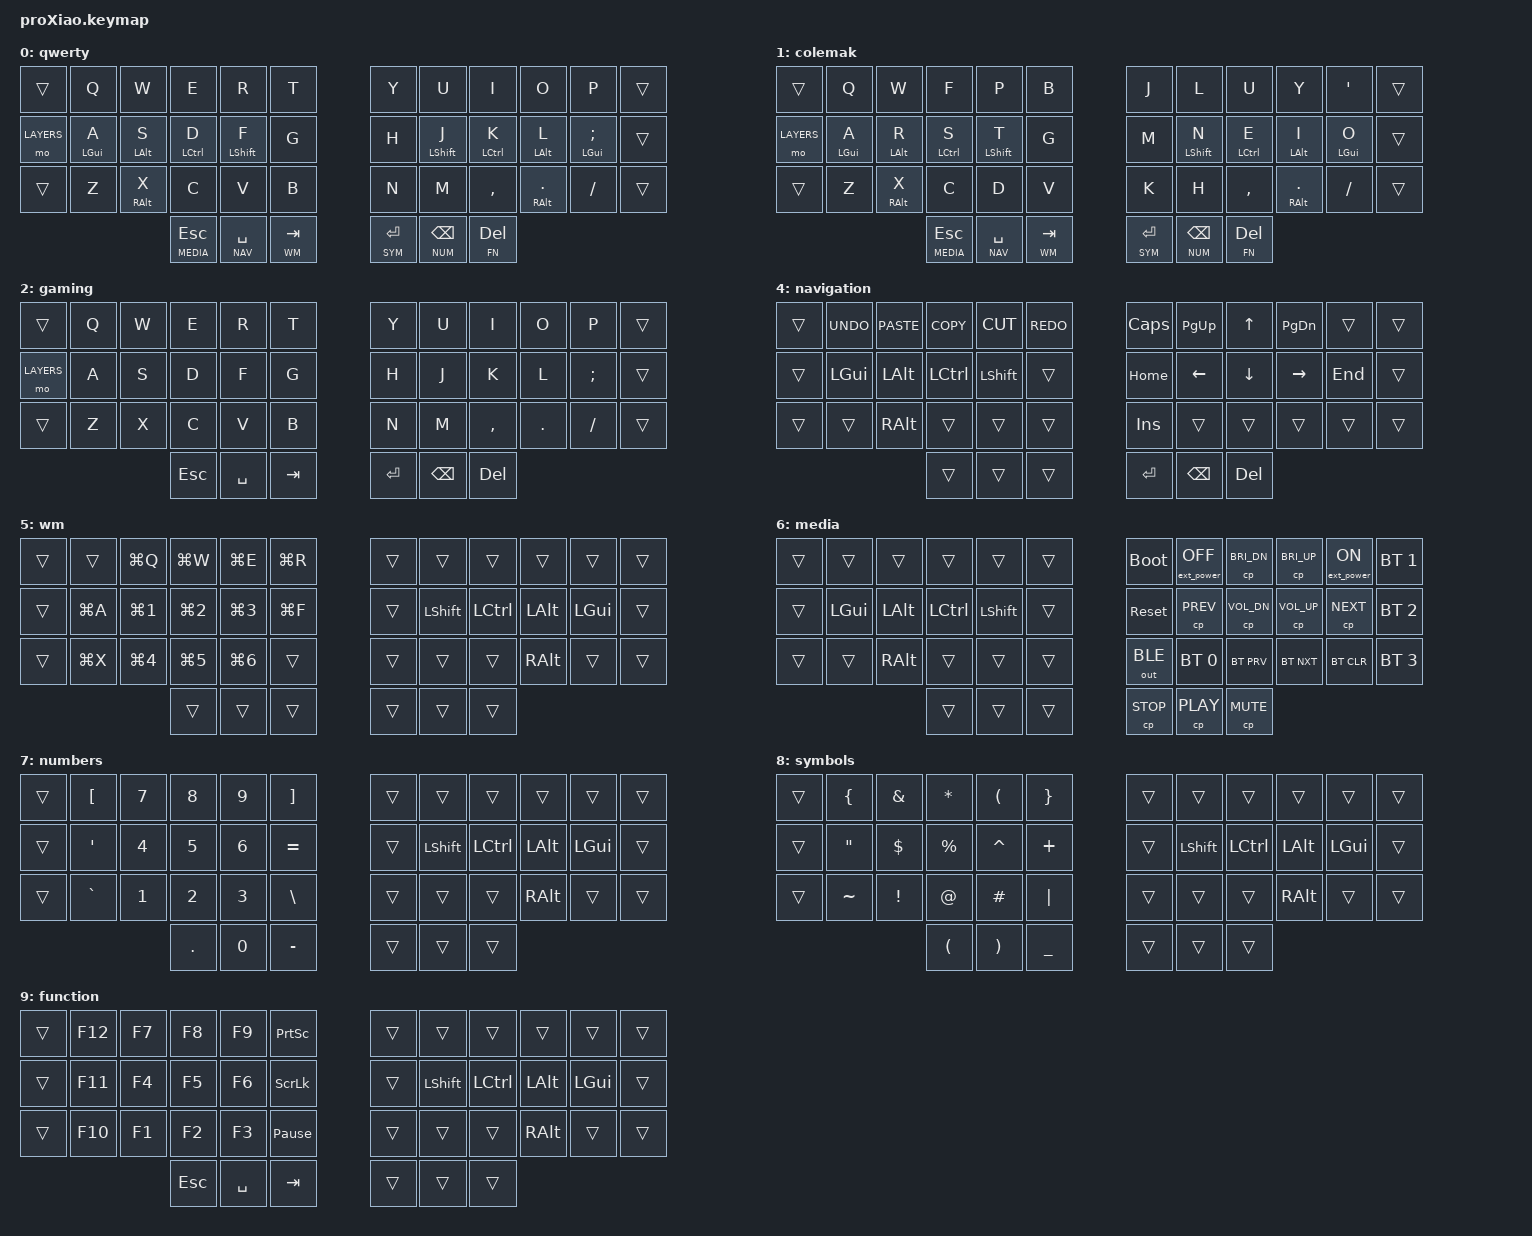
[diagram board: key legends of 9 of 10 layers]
// Jason Liu Layout for Corne 3
// https://github.com/jasoneliu/zmk-config/blob/main/config/corne.keymap
//

#include <behaviors.dtsi>
#include <dt-bindings/zmk/keys.h>
#include <dt-bindings/zmk/bt.h>
#include <dt-bindings/zmk/ext_power.h>
#include <dt-bindings/zmk/outputs.h>

#include "../zmk-nodefree-config/helper.h"
#include "includes/settings.dtsi"

// Layer Definitions
#define QWERTY 0
#define COLEMAK 1
#define GAMING 2
#define LAYERS 3
#define NAV 4
#define WM 5
#define MEDIA 6
#define NUM 7
#define SYM 8
#define FN 9

#define ___ &trans
#define QUICK_TAP_MS 175


/* Homerow mods */
#include "../zmk-nodefree-config/keypos_def/keypos_42keys.h"

#define KEYS_L LT0 LT1 LT2 LT3 LT4 LM0 LM1 LM2 LM3 LM4 LB0 LB1 LB2 LB3 LB4  // left hand
#define KEYS_R RT0 RT1 RT2 RT3 RT4 RM0 RM1 RM2 RM3 RM4 RB0 RB1 RB2 RB3 RB4  // right hand
#define THUMBS LH2 LH1 LH0 RH0 RH1 RH2                                      // thumbs

#define MAKE_HRM(NAME, HOLD, TAP, TRIGGER_POS) \
    ZMK_BEHAVIOR(NAME, hold_tap, \
        flavor = "balanced"; \
        tapping-term-ms = <280>; \
        quick-tap-ms = <QUICK_TAP_MS>; \
        require-prior-idle-ms = <150>; \
        bindings = <HOLD>, <TAP>; \
        hold-trigger-key-positions = <TRIGGER_POS>; \
        hold-trigger-on-release; \
    )
MAKE_HRM(hml, &kp, &kp, KEYS_R THUMBS)  // left-hand HRMs
MAKE_HRM(hmr, &kp, &kp, KEYS_L THUMBS)  // right-hand HRMs


// Keymap configuration (Colemak-DHm)
/ {
    keymap {
        compatible = "zmk,keymap";

        qwerty {
// -----------------------------------------------------------------------------------------------------------------------------
// |        |   Q    |   W    |     E     |     R     |     T     | # |     Y     |     U    |    I    |    O   |   P    |     |
// | LAYERS | A/LGUI | S/LALT |  D/LCTRL  |  F/LSHFT  |     G     | # |     H     | J/LSHFT  | K/LCTRR | L/LALT | ;/LGUI |     |
// |        |   Z    | X/RALT |     C     |     V     |     B     | # |     N     |     M    |    ,    | ./RALT |   /    |     |
//                            | ESC/MEDIA | SPACE/NAV | TAB/WM    | # | ENTER/SYM | BSPC/NUM | DEL/FN  |

            bindings = <
&trans      &kp Q       &kp W       &kp E          &kp R          &kp T                &kp Y          &kp U         &kp I          &kp O         &kp P          &trans
&mo LAYERS  &mt LGUI A  &mt LALT S  &mt LCTRL D    &mt LSHFT F    &kp G                &kp H          &mt LSHFT J   &mt LCTRL K    &mt LALT L    &mt LGUI SEMI  &trans
&trans      &kp Z       &mt RALT X  &kp C          &kp V          &kp B                &kp N          &kp M         &kp CMMA       &mt RALT DOT  &kp FSLH       &trans
                                    &lt MEDIA ESC  &lt NAV SPACE  &lt WM TAB           &lt SYM ENTER  &lt NUM BSPC  &lt FN DEL
            >;
        };

        colemak {
// -----------------------------------------------------------------------------------------------------------------------------
// |        |   Q    |   W    |     F     |     P     |     B     | # |     J     |    L     |    U    |    Y   |   '    |     |
// | LAYERS | A/LGUI | R/LALT |  S/LCTRL  |  T/LSHFT  |     G     | # |     M     | N/LSHFT  | E/LCTRL | I/LALT | O/LGUI |     |
// |        |   Z    | X/RALT |     C     |     D     |     V     | # |     K     |    H     |    ,    | ./RALT |   /    |     |
//                            | ESC/MEDIA | SPACE/NAV | TAB/WM    | # | ENTER/SYM | BSPC/NUM | DEL/FN  |

            bindings = <
&trans      &kp Q       &kp W       &kp F          &kp P          &kp B                &kp J          &kp L         &kp U          &kp Y         &kp SQT     &trans
&mo LAYERS  &mt LGUI A  &mt LALT R  &mt LCTRL S    &mt LSHFT T    &kp G                &kp M          &mt LSHFT N   &mt LCTRL E    &mt LALT I    &mt LGUI O  &trans
&trans      &kp Z       &mt RALT X  &kp C          &kp D          &kp V                &kp K          &kp H         &kp CMMA       &mt RALT DOT  &kp FSLH    &trans
                                    &lt MEDIA ESC  &lt NAV SPACE  &lt WM TAB           &lt SYM ENTER  &lt NUM BSPC  &lt FN DEL
            >;
        };

        gaming {
// ----------------------------------------------------------------------------------------------------
// |        |   Q   |   W   |   E   |   R   |   T   | # |   Y   |   U   |   I   |   O   |   P   |     |
// | LAYERS |   A   |   S   |   D   |   F   |   G   | # |   H   |   J   |   K   |   L   |   ;   |     |
// |        |   Z   |   X   |   C   |   V   |   B   | # |   N   |   M   |   ,   |   .   |   /   |     |
//                          |  ESC  | SPACE |  TAB  | # | ENTER | BSPC  |  DEL  |

            bindings = <
&trans      &kp Q  &kp W  &kp E    &kp R      &kp T          &kp Y      &kp U     &kp I     &kp O    &kp P     &trans
&mo LAYERS  &kp A  &kp S  &kp D    &kp F      &kp G          &kp H      &kp J     &kp K     &kp L    &kp SEMI  &trans
&trans      &kp Z  &kp X  &kp C    &kp V      &kp B          &kp N      &kp M     &kp CMMA  &kp DOT  &kp FSLH  &trans
                          &kp ESC  &kp SPACE  &kp TAB        &kp ENTER  &kp BSPC  &kp DEL
            >;
        };

        layers {
// ----------------------------------------------------------------------------------------
// |      |     |     |     |     |     | # |     |        |         |        |     |     |
// | HELD |     |     |     |     |     | # |     | QWERTY | COLEMAK | GAMING |     |     |
// |      |     |     |     |     |     | # |     |        |         |        |     |     |
//                    |     |     |     | # |     |        |         |

            bindings = <
&trans  &trans  &trans  &trans  &trans  &trans        &trans  &trans      &trans       &trans      &trans  &trans
&trans  &trans  &trans  &trans  &trans  &trans        &trans  &to QWERTY  &to COLEMAK  &to GAMING  &trans  &trans
&trans  &trans  &trans  &trans  &trans  &trans        &trans  &trans      &trans       &trans      &trans
                        &trans  &trans  &trans        &trans  &trans      &trans
            >;
        };

        navigation {
// --------------------------------------------------------------------------------------------
// |     | UNDO | PASTE | COPY  | CUT   | REDO | # | CAPS  | PGUP | UP   | PGDN  |      |     |
// |     | LGUI | LALT  | LCTRL | LSHFT |      | # | HOME  | LEFT | DOWN | RIGHT | END  |     |
// |     |      | RALT  |       |       |      | # | INS   |      |      |       |      |     |
//                      |       | HELD  |      | # | ENTER | BSPC | DEL  |

            bindings = <
&trans  &kp K_UNDO  &kp K_PASTE  &kp K_COPY  &kp K_CUT  &kp K_REDO        &kp CAPSLOCK  &kp PG_UP  &kp UP    &kp PG_DN  &trans   &trans
&trans  &kp LGUI    &kp LALT     &kp LCTRL   &kp LSHFT  &trans            &kp HOME      &kp LEFT   &kp DOWN  &kp RIGHT  &kp END  &trans
&trans  &trans      &kp RALT     &trans      &trans     &trans            &kp INS       &trans     &trans    &trans     &trans   &trans
                                 &trans      &trans     &trans            &kp ENTER     &kp BSPC   &kp DEL
            >;
        };

// Window manager hotkeys

        wm {
// -----------------------------------------------------------------------------------------
// |     |      | WINQ | WINW | WINE | WINR | # |      |       |       |      |      |     |
// |     | WINA | WIN1 | WIN2 | WIN3 | WINF | # |      | LSHFT | LCTRL | LALT | LGUI |     |
// |     | WINX | WIN4 | WIN5 | WIN6 |      | # |      |       |       | RALT |      |     |
//                     |      |      | HELD | # |      |       |       |

            bindings = <
&trans  &trans     &kp LG(Q)   &kp LG(W)   &kp LG(E)   &kp LG(R)        &trans  &trans     &trans     &trans    &trans    &trans
&trans  &kp LG(A)  &kp LG(N1)  &kp LG(N2)  &kp LG(N3)  &kp LG(F)        &trans  &kp LSHFT  &kp LCTRL  &kp LALT  &kp LGUI  &trans
&trans  &kp LG(X)  &kp LG(N4)  &kp LG(N5)  &kp LG(N6)  &trans           &trans  &trans     &trans     &kp RALT  &trans    &trans
                               &trans      &trans      &trans           &trans  &trans     &trans
            >;
        };

        media {
// ------------------------------------------------------------------------------------------------------
// |     |      |      |       |       |      | # | BOOTLOAD | EP_OFF | BR_D   | BR_U   | EP_ON  | BT_1 |
// |     | LGUI | LALT | LCTRL | LSHFT |      | # | RESET    | PREV   | VOL_D  | VOL_U  | NEXT   | BT_2 |
// |     |      | RALT |       |       |      | # | OUT_BLE  | BT_0   | BT_PRV | BT_NXT | BT_CLR | BT_3 |
//                     | HELD  |       |      | # | STOP     | PLAY   | MUTE   |

            bindings = <
&trans  &trans    &trans    &trans     &trans     &trans        &bootloader   &ext_power EP_OFF  &cp C_BRI_DN  &cp C_BRI_UP  &ext_power EP_ON  &bt BT_SEL 1
&trans  &kp LGUI  &kp LALT  &kp LCTRL  &kp LSHFT  &trans        &sys_reset    &cp C_PREV         &cp C_VOL_DN  &cp C_VOL_UP  &cp C_NEXT        &bt BT_SEL 2
&trans  &trans    &kp RALT  &trans     &trans     &trans        &out OUT_BLE  &bt BT_SEL 0       &bt BT_PRV    &bt BT_NXT    &bt BT_CLR        &bt BT_SEL 3
                            &trans     &trans     &trans        &cp C_STOP    &cp C_PLAY         &cp C_MUTE
            >;
        };

        numbers {
// -----------------------------------------------------------------------------------
// |     |  [  |  7  |  8  |  9  |  ]  | # |     |       |       |      |      |     |
// |     |  '  |  4  |  5  |  6  |  =  | # |     | LSHFT | LCTRL | LALT | LGUI |     |
// |     |  `  |  1  |  2  |  3  |  \  | # |     |       |       | RALT |      |     |
//                   |  .  |  0  |  -  | # |     | HELD  |       |

            bindings = <
&trans  &kp LBKT   &kp N7  &kp N8   &kp N9  &kp RBKT         &trans  &trans     &trans     &trans    &trans    &trans
&trans  &kp SQT    &kp N4  &kp N5   &kp N6  &kp EQUAL        &trans  &kp LSHFT  &kp LCTRL  &kp LALT  &kp LGUI  &trans
&trans  &kp GRAVE  &kp N1  &kp N2   &kp N3  &kp BSLH         &trans  &trans     &trans     &kp RALT  &trans    &trans
                           &kp DOT  &kp N0  &kp MINUS        &trans  &trans     &trans
            >;
        };

        symbols {
// ------------------------------------------------------------------------------------
// |     |  {  |  &  |  *  |  (  |  }  | # |      |       |       |      |      |     |
// |     |  "  |  $  |  %  |  ^  |  +  | # |      | LSHFT | LCTRL | LALT | LGUI |     |
// |     |  ~  |  !  |  @  |  #  |  |  | # |      |       |       | RALT |      |     |
//                   |  (  |  )  |  _  | # | HELD |       |       |

            bindings = <
&trans  &kp LBRC   &kp AMPS  &kp ASTRK  &kp LPAR   &kp RBRC              &trans  &trans     &trans     &trans    &trans    &trans
&trans  &kp DQT    &kp DLLR  &kp PRCNT  &kp CARET  &kp PLUS              &trans  &kp LSHFT  &kp LCTRL  &kp LALT  &kp LGUI  &trans
&trans  &kp TILDE  &kp EXCL  &kp AT     &kp HASH   &kp PIPE              &trans  &trans     &trans     &kp RALT  &trans    &trans
                             &kp LPAR   &kp RPAR   &kp UNDERSCORE        &trans  &trans     &trans
            >;
        };

        function {
// ------------------------------------------------------------------------------------------
// |     |  F12 |  F7  |  F8  |  F9   | PSCRN | # |     |       |       |      |      |     |
// |     |  F11 |  F4  |  F5  |  F6   | SLCK  | # |     | LSHFT | LCTRL | LALT | LGUI |     |
// |     |  F10 |  F1  |  F2  |  F3   | PAUSE | # |     |       |       | RALT |      |     |
//                     | ESC  | SPACE |  TAB  | # |     |       | HELD  |

            bindings = <
&trans  &kp F12  &kp F7  &kp F8   &kp F9     &kp PSCRN              &trans  &trans     &trans     &trans    &trans    &trans
&trans  &kp F11  &kp F4  &kp F5   &kp F6     &kp SLCK               &trans  &kp LSHFT  &kp LCTRL  &kp LALT  &kp LGUI  &trans
&trans  &kp F10  &kp F1  &kp F2   &kp F3     &kp PAUSE_BREAK        &trans  &trans     &trans     &kp RALT  &trans    &trans
                         &kp ESC  &kp SPACE  &kp TAB                &trans  &trans     &trans
            >;
        };
    };
};
